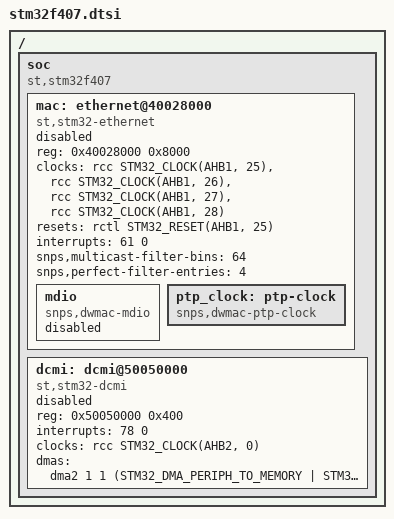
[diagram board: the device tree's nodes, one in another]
/*
 * Copyright (c) 2017 Erwin Rol <erwin@erwinrol.com>
 *
 * SPDX-License-Identifier: Apache-2.0
 */

#include <st/f4/stm32f405.dtsi>

/ {
	soc {
		compatible = "st,stm32f407", "st,stm32f4", "simple-bus";

		mac: ethernet@40028000 {
			compatible = "st,stm32-ethernet", "snps,dwmac";
			reg = <0x40028000 0x8000>;
			clock-names = "stm-eth", "mac-clk-tx", "mac-clk-rx", "mac-clk-ptp";
			clocks = <&rcc STM32_CLOCK(AHB1, 25)>,
				 <&rcc STM32_CLOCK(AHB1, 26)>,
				 <&rcc STM32_CLOCK(AHB1, 27)>,
				 <&rcc STM32_CLOCK(AHB1, 28)>;
			resets = <&rctl STM32_RESET(AHB1, 25)>;
			interrupts = <61 0>;
			snps,multicast-filter-bins = <64>;
			snps,perfect-filter-entries = <4>;
			status = "disabled";

			mdio: mdio {
				compatible = "snps,dwmac-mdio";
				#address-cells = <1>;
				#size-cells = <0>;
				status = "disabled";
			};

			ptp_clock: ptp-clock {
				compatible = "snps,dwmac-ptp-clock";
			};
		};

		dcmi: dcmi@50050000 {
			compatible = "st,stm32-dcmi";
			reg = <0x50050000 0x400>;
			interrupts = <78 0>;
			interrupt-names = "dcmi";
			clocks = <&rcc STM32_CLOCK(AHB2, 0)>;
			dmas = <&dma2 1 1 (STM32_DMA_PERIPH_TO_MEMORY | STM32_DMA_PERIPH_NO_INC |
					   STM32_DMA_MEM_INC | STM32_DMA_PERIPH_32BITS |
					   STM32_DMA_MEM_32BITS |
					   STM32_DMA_PRIORITY_HIGH) STM32_DMA_FIFO_FULL>;
			status = "disabled";
		};
	};
};
